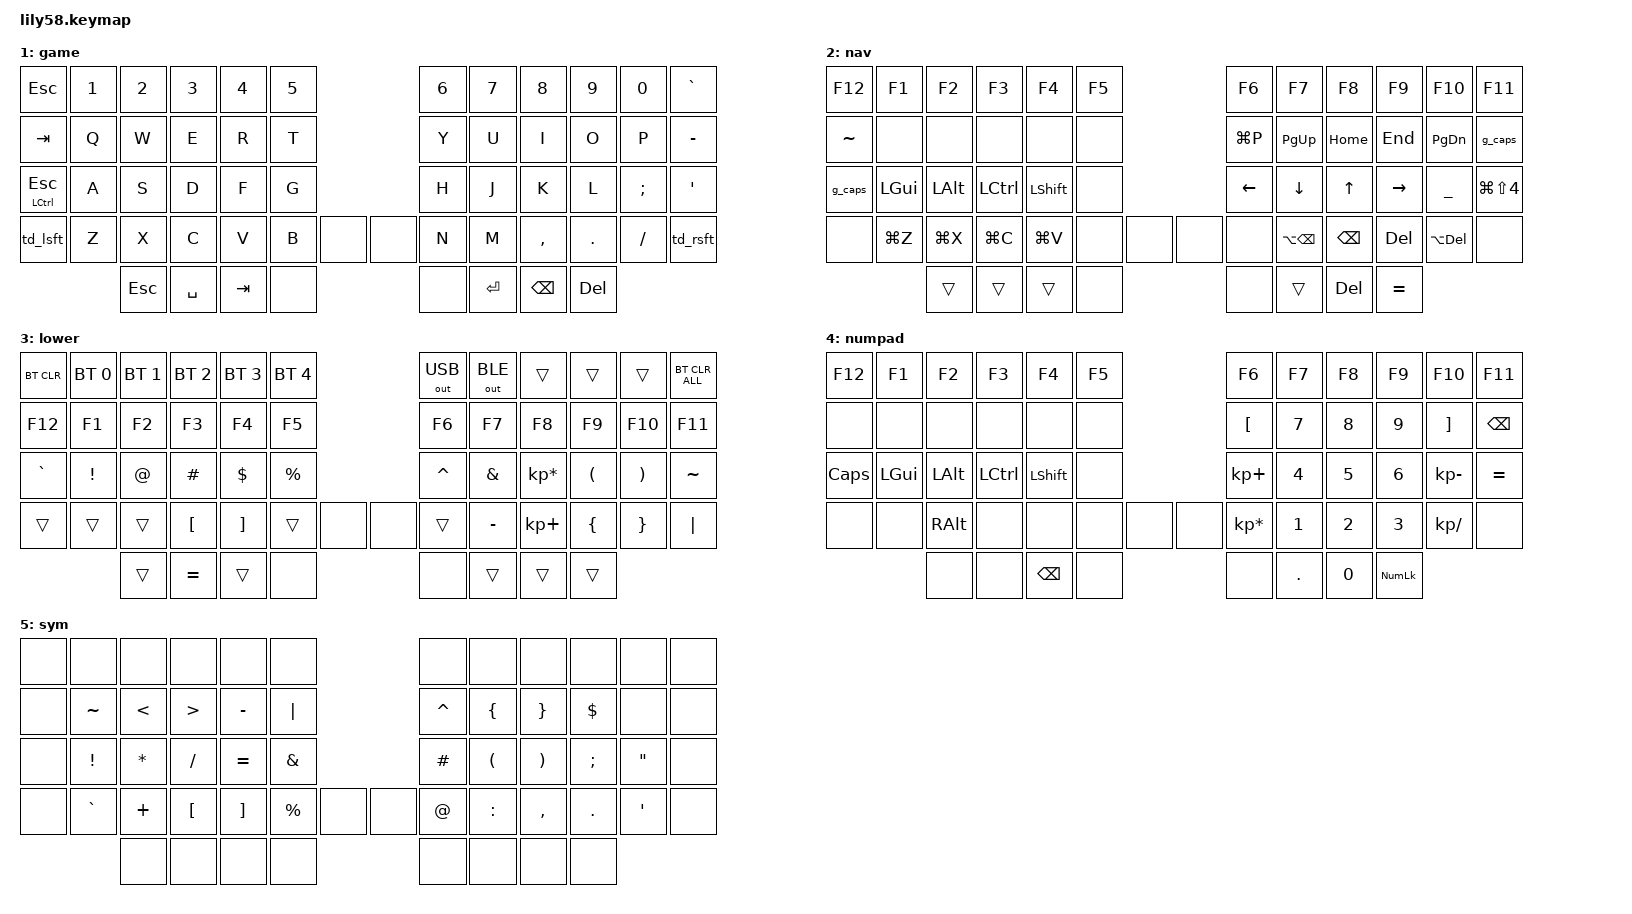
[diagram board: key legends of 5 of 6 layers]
/*
 * Copyright (c) 2020 The ZMK Contributors
 *
 * SPDX-License-Identifier: MIT
 */

#include <behaviors.dtsi>
#include <dt-bindings/zmk/keys.h>
#include <dt-bindings/zmk/bt.h>
#include <dt-bindings/zmk/ext_power.h>
#include <dt-bindings/zmk/outputs.h>


#define AS(keycode) &as LS(keycode) keycode     // Autoshift Macro
#define BASE 0
#define GAME 1
#define NAV  2
#define LOWER 3
#define NUMPAD 4
#define SYM 5
#define KEYS_L 0 1 2 3 4 5 12 13 14 15 16 17 24 25 26 27 28 29 36 37 38 39 40 41  // left hand (no encoder, no thumbs)
#define KEYS_R 6 7 8 9 10 11 18 19 20 21 22 23 30 31 32 33 34 35 44 45 46 47 48 49  // right hand (no encoder, no thumbs)
#define THUMBS 50 51 52 53 54 55 56 57  // all thumb keys

// Lily58 key position definitions
//
//   58 KEY MATRIX / LAYOUT MAPPING
//
//   ╭────────────────────────────┬────────────────────────────╮ ╭─────────────────────────────┬─────────────────────────────╮
//   │  0   1   2   3   4   5     │      6   7   8   9  10  11 │ │ LN5 LN4 LN3 LN2 LN1 LN0     │     RN0 RN1 RN2 RN3 RN4 RN5 │
//   │ 12  13  14  15  16  17     │     18  19  20  21  22  23 │ │ LT5 LT4 LT3 LT2 LT1 LT0     │     RT0 RT1 RT2 RT3 RT4 RT5 │
//   │ 24  25  26  27  28  29     │     30  31  32  33  34  35 │ │ LM5 LM4 LM3 LM2 LM1 LM0     │     RM0 RM1 RM2 RM3 RM4 RM5 │
//   │ 36  37  38  39  40  41  42 │ 43  44  45  46  47  48  49 │ │ LB5 LB4 LB3 LB2 LB1 LB0 LEC │ REC RB0 RB1 RB2 RB3 RB4 RB5 │
//   ╰───────────╮ 50  51  52  53 │ 54  55  56  57 ╭───────────╯ ╰───────────╮ LH3 LH2 LH1 LH0 │ RH0 RH1 RH2 RH3 ╭───────────╯
//               ╰────────────────┴────────────────╯                         ╰─────────────────┴─────────────────╯





/ {
    /*
     * CUSTOM BEHAVIORS
     * Based on Miryoku preferences:
     * - Tap-preferred flavor for mod-taps
     * - 200ms tapping term
     */
    behaviors {
        // Home Row Mods - Left Hand (Hold=GUI/Alt/Ctrl/Shift, Tap=Key)
        hml: homerow_mods_left {
            compatible = "zmk,behavior-hold-tap";
            #binding-cells = <2>;
            flavor = "balanced";
            tapping-term-ms = <280>;
            quick-tap-ms = <175>;
            require-prior-idle-ms = <100>;
            bindings = <&kp>, <&kp>;
            hold-trigger-key-positions = <KEYS_R THUMBS>;
            hold-trigger-on-release;
        };

        hmr: homerow_mods_right {
            compatible = "zmk,behavior-hold-tap";
            #binding-cells = <2>;
            flavor = "balanced";
            tapping-term-ms = <280>;
            quick-tap-ms = <175>;
            require-prior-idle-ms = <100>;
            bindings = <&kp>, <&kp>;
            hold-trigger-key-positions = <KEYS_L THUMBS>;
            hold-trigger-on-release;
        };

        // Layer Tap (Hold=Layer, Tap=Key)
        lt_b: layer_tap_balanced {
            compatible = "zmk,behavior-hold-tap";
            #binding-cells = <2>;
            flavor = "balanced";
            tapping-term-ms = <200>;
            bindings = <&mo>, <&kp>;
        };

        // Global Shift Functions (Caps Word on Shift+Caps)
        g_caps: global_caps_word {
            compatible = "zmk,behavior-mod-morph";
            #binding-cells = <0>;
            bindings = <&caps_word>, <&kp CAPS>;
            mods = <(MOD_LSFT|MOD_RSFT)>;
        };
        td_lsft: tap_dance_left_shift {
            compatible = "zmk,behavior-tap-dance";
            #binding-cells = <0>;
            tapping-term-ms = <200>;
            bindings = <&kp LSHFT>, <&caps_word>;
        };
        td_rsft: tap_dance_right_shift {
            compatible = "zmk,behavior-tap-dance";
            #binding-cells = <0>;
            tapping-term-ms = <200>;
            bindings = <&kp RSHFT>, <&caps_word>;
        };
        hold_space: hold_space {
            compatible = "zmk,behavior-hold-tap";
            #binding-cells = <2>;
            flavor = "tap-preferred";
            tapping-term-ms = <200>;
            bindings = <&kp>, <&kp>;
        };
        as: auto_shift {
            compatible = "zmk,behavior-hold-tap";
            #binding-cells = <2>;
            tapping_term_ms = <135>;
            quick_tap_ms = <0>;
            flavor = "tap-preferred";
            bindings = <&kp>, <&kp>;
        };

        // Layer-tap with sticky-key tap (Hold=Layer, Tap=Sticky modifier)
        lt_sk: layer_tap_sticky {
            compatible = "zmk,behavior-hold-tap";
            #binding-cells = <2>;
            flavor = "balanced";
            tapping-term-ms = <200>;
            bindings = <&mo>, <&sk>;
        };
    };
};

/ {
  combos {
    compatible = "zmk,combos";

    /* --- Kanata combo parity ---
     * Kanata's (esc 1) -> lrld reload chord has no ZMK firmware equivalent.
     */
    combo_jk_hyper {
      timeout-ms = <50>;
      key-positions = <31 32>; /* J(31) + K(32) */
      bindings = <&sk LC(LA(LS(LGUI)))>;
    };

    combo_kl_alt_bspc {
      timeout-ms = <50>;
      key-positions = <32 33>; /* K(32) + L(33) */
      bindings = <&kp LA(BSPC)>;
    };

    combo_jl_hyper_space {
      timeout-ms = <50>;
      key-positions = <31 33>; /* J(31) + L(33) */
      bindings = <&kp LC(LA(LS(LG(SPACE))))>;
    };

    combo_cv_spc {
      timeout-ms = <50>;
      key-positions = <39 40>; /* C(39) + V(40) */
      bindings = <&kp SPACE>;
    };

    combo_fd_hyper {
      timeout-ms = <50>;
      key-positions = <27 28>; /* D(27) + F(28) */
      bindings = <&sk LC(LA(LS(LGUI)))>;
    };

    combo_sd_f13 {
      timeout-ms = <50>;
      key-positions = <26 27>; /* S(26) + D(27) */
      bindings = <&kp F13>;
    };

    combo_sf_f16 {
      timeout-ms = <50>;
      key-positions = <26 28>; /* S(26) + F(28) */
      bindings = <&kp F16>;
    };

    combo_ui_cmd_grave {
      timeout-ms = <50>;
      key-positions = <19 20>; /* U(19) + I(20) */
      bindings = <&kp LG(GRAVE)>;
    };
  };
};




/ {
    keymap {
        compatible = "zmk,keymap";

        default_layer {
// ------------------------------------------------------------------------------------------------------------
// |  ESC  |  1  |  2  |  3   |  4   |  5   |                   |  6   |  7    |  8    |  9   |   0   |   `   |
// |  TAB  |  Q  |  W  |  E   |  R   |  T   |                   |  Y   |  U    |  I    |  O   |   P   |   -   |
// |  CTRL |  A  |  S  |  D   |  F   |  G   |                   |  H   |  J    |  K    |  L   |   ;   |   '   |
// | SHIFT |  Z  |  X  |  C   |  V   |  B   |  n/a   |  |  n/a  |  N   |  M    |  ,    |  .   |   /   | SHIFT |
//                     | GUI  | LOWER| SPACE|  n/a   |  |  n/a  | ENTER| RAISE | BSPC  |
// Note: Silakka54 has 54 keys - the 4 positions marked n/a are not present (inner thumb + encoder positions)
            display-name = "base";
            bindings = <
&kp ESC             &kp N1          &kp N2          &kp N3          &kp N4          &kp N5                          &kp N6          &kp N7          &kp N8          &kp N9          &kp N0          &kp MINUS
&kp TAB             &kp Q           &kp W           &kp E           &kp R           &kp T                           &kp Y           &kp U           &kp I           &kp O           &kp P           &kp BSLH
&mt LGUI ESC        &hml LCTRL A     &hml LALT S     &hml LGUI D    &hml LSHIFT F   &kp G                           &kp H           &hmr RSHIFT J   &hmr RGUI K     &hmr RALT L     &hmr RCTRL SEMI  &kp SQT
&td_lsft            &kp Z           &kp X           &kp C           &kp V           &kp B       &none     &none     &kp N           &kp M           &kp COMMA       &kp DOT         AS(FSLH)        &td_rsft
                                    &lt 5 DEL       &lt 2 BSPC      &lt 4 TAB       &none                           &none           &lt 4 RET       &lt 3 SPC       &lt_sk 5 LC(LA(LS(LGUI)))
            >;
        };

        game_layer {
            display-name = "game";
            bindings = <
&kp ESC             &kp N1          &kp N2          &kp N3          &kp N4          &kp N5                          &kp N6          &kp N7          &kp N8          &kp N9          &kp N0          &kp GRAVE
&kp TAB             &kp Q           &kp W           &kp E           &kp R           &kp T                           &kp Y           &kp U           &kp I           &kp O           &kp P           &kp MINUS
&mt LCTRL ESC       &kp A           &kp S           &kp D           &kp F           &kp G                           &kp H           &kp J           &kp K           &kp L           &kp SEMI        &kp SQT
&td_lsft            &kp Z           &kp X           &kp C           &kp V           &kp B       &none     &none     &kp N           &kp M           &kp COMMA       &kp DOT         &kp FSLH        &td_rsft
                                    &kp ESC         &kp SPACE       &kp TAB         &none                           &none           &kp RET         &kp BSPC        &kp DEL
            >;
        };

        nav_layer {
            display-name = "nav";
            bindings = <
&kp F12    &kp F1       &kp F2       &kp F3       &kp F4       &kp F5                     &kp F6       &kp F7       &kp F8        &kp F9      &kp F10      &kp F11
&kp TILDE  &none        &none        &none        &none        &none                      &kp LG(P)    &kp PG_UP    &kp HOME      &kp END     &kp PG_DN    &g_caps
&g_caps    &kp LGUI     &kp LALT     &kp LCTRL    &kp LSHFT    &none                      &kp LEFT     &kp DOWN     &kp UP        &kp RIGHT   &kp UNDER    &kp LG(LS(N4))
&none      &kp LG(Z)    &kp LG(X)    &kp LG(C)    &kp LG(V)    &none    &none     &none   &none        &kp LA(BSPC) &kp BSPC      &kp DEL     &kp LA(DEL)  &none
                                     &trans       &trans       &trans   &none     &none   &trans       &kp DEL      &kp EQUAL
            >;
        };

//         nav_layer {
//             display-name = "Nav";
//             bindings = <
// &none      &none        &none        &none        &none        &none                      &none        &none        &none         &none       &none        &none
// &none      &none        &none        &none        &none        &none                      &none        &none        &none         &none       &none        &none
// &none      &none        &none        &none        &none        &none                      &none        &none        &none         &none       &none        &none
// &none      &none        &none        &none        &none        &none    &none     &none   &none        &none        &none         &none       &none        &none
//                                      &none        &none        &none    &none     &none   &none        &none        &none
//             >;
//         };

        lower_layer {
            display-name = "lower";
            bindings = <
&bt BT_CLR      &bt BT_SEL 0        &bt BT_SEL 1        &bt BT_SEL 2        &bt BT_SEL 3        &bt BT_SEL 4                &out OUT_USB        &out OUT_BLE        &trans                  &trans          &trans          &bt BT_CLR_ALL
&kp F12         &kp F1             &kp F2               &kp F3              &kp F4              &kp F5                      &kp F6              &kp F7              &kp F8                  &kp F9          &kp F10         &kp F11
&kp GRAVE       &kp EXCL            &kp AT              &kp HASH            &kp DOLLAR          &kp PRCNT                   &kp CARET           &kp AMPS            &kp KP_MULTIPLY         &kp LPAR        &kp RPAR        &kp TILDE
&trans          &trans              &trans              &kp LBKT            &kp RBKT            &trans    &none     &none   &trans              &kp MINUS           &kp KP_PLUS             &kp LBRC        &kp RBRC        &kp PIPE
                                                        &trans              &kp EQUAL           &trans    &none     &none   &trans              &trans              &trans
            >;
        };

numpad_layer {
    display-name = "numpad";
    bindings = <
        &kp F12     &kp F1      &kp F2      &kp F3      &kp F4      &kp F5                          &kp F6           &kp F7      &kp F8      &kp F9      &kp F10     &kp F11
        &none       &none       &none       &none       &none       &none                           &kp LBKT         &kp N7      &kp N8      &kp N9      &kp RBKT    &kp BSPC
        &kp CAPS    &kp LGUI    &kp LALT    &kp LCTRL   &kp LSHIFT  &none                           &kp KP_PLUS      &kp N4      &kp N5      &kp N6      &kp KP_MINUS &kp EQUAL
        &none       &none       &kp RALT    &none       &none       &none     &none      &none      &kp KP_MULTIPLY  &kp N1      &kp N2      &kp N3      &kp KP_SLASH &none
                                            &none       &none       &kp BSPC  &none      &none      &kp DOT          &kp N0      &kp KP_NLCK
    >;
};

        sym_layer {
            display-name = "sym";
            bindings = <
&none      &none        &none        &none        &none        &none                       &none        &none        &none         &none       &none        &none
&none      &kp TILDE    &kp LT       &kp GT       &kp MINUS    &kp PIPE                    &kp CARET    &kp LBRC     &kp RBRC      &kp DOLLAR  &none        &none
&none      &kp EXCL     &kp ASTRK    &kp SLASH    &kp EQUAL    &kp AMPS                    &kp HASH     &kp LPAR     &kp RPAR      &kp SEMI    &kp DQT      &none
&none      &kp GRAVE    &kp PLUS     &kp LBKT     &kp RBKT     &kp PRCNT &none     &none   &kp AT       &kp COLON    &kp COMMA     &kp DOT     &kp SQT      &none
                                     &none        &none        &none     &none     &none   &none        &none        &none
            >;
        };

        extra_1 {
            status = "reserved";
        };

        extra_2 {
            status = "reserved";
        };

        extra_3 {
            status = "reserved";
        };
    };
};
